AUTOSAR XML (schema 00046)
package /ComponentTypes
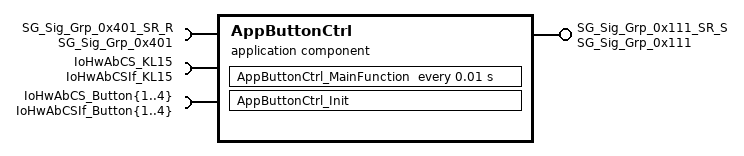
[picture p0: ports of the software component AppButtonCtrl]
  application sw component type AppButtonCtrl
    require port SG_Sig_Grp_0x401_SR_R: nonqueued-receiver-com-spec{data-element=SG_Sig_Grp_0x401, filter=data-filter-type=ALWAYS, init-value=fields=[Button1_Control:0, Button2_Control:0, Button3_Control:0, Button4_Control:0]}, required-interface=SG_Sig_Grp_0x401
    provide port SG_Sig_Grp_0x111_SR_S: nonqueued-sender-com-spec{data-element=SG_Sig_Grp_0x111, init-value=fields=[Button1_State:0, Button2_State:0, Button3_State:0, Button4_State:0]}, provided-interface=SG_Sig_Grp_0x111
    5 x require port:
      IoHwAbCS_KL15: required-com-specs=[IoHwAbOp_KL15_Read], required-interface=IoHwAbCSIf_KL15
      IoHwAbCS_Button{1..4}: required-com-specs=[IoHwAbOp_Button{1..4}_Read], required-interface=IoHwAbCSIf_Button{1..4}
    behavior AppButtonCtrl_InternalBehavior
      timing event TMT_AppButtonCtrl_MainFunction: start-on-event=AppButtonCtrl_MainFunction, period=0.01
      init event AppButtonCtrl_InitEvent: start-on-event=AppButtonCtrl_Init
      runnable AppButtonCtrl_MainFunction
        data-receive-point-by-arguments:
          access REC_SG_Sig_Grp_0x401_SR_R_SG_Sig_Grp_0x401: accessed-variable=SG_Sig_Grp_0x401_SR_R.SG_Sig_Grp_0x401
        data-send-points:
          access SEND_SG_Sig_Grp_0x111_SR_S_SG_Sig_Grp_0x111: accessed-variable=SG_Sig_Grp_0x111_SR_S.SG_Sig_Grp_0x111
        5 x sync call:
          SC_IoHwAbCS_Button{1..4}_IoHwAbOp_Button{1..4}_Read: operation=IoHwAbCS_Button{1..4}.IoHwAbOp_Button{1..4}_Read
          SC_IoHwAbCS_KL15_IoHwAbOp_KL15_Read: operation=IoHwAbCS_KL15.IoHwAbOp_KL15_Read
      runnable AppButtonCtrl_Init
        4 x sync call:
          SC_IoHwAbCS_Button{1..4}_IoHwAbOp_Button{1..4}_Write: operation=IoHwAbCS_Button{1..4}
  swc implementation AppButtonCtrl_Implementation: behavior=AppButtonCtrl_InternalBehavior
